# PY32F032xx register map
Vendor: Puya; Series: PY32F0; File version: 1.0.0
Arm 32-bit Cortex-M0+ Microcontroller based device, CPU clock up to 48 MHz.
CPU: CM0+ r0p1, little endian, no MPU, no FPU, 4 interrupt priority bits
Registers are 32-bit, read-write, reset 0x0 unless marked. A register's access mark holds for its fields unless they carry their own. Offsets are from the block's base; lines under a group give offsets from that group; [hi:lo] are bit positions; {n}, {i} and the like mark numbered series; 'fields as' and 'values as' point back to an identical list; <NAME> marks a mode.

## Memory map
0x40000400 TIM3 size 0x3F0
0x40002000 TIM14 size 0x400 — General purpose timer
0x40002800 RTC size 0x400 — Real time clock
0x40002C00 WWDG size 0x400 — Window watchdog
0x40003000 IWDG size 0x400 — Independent watchdog
0x40003800 SPI2 size 0x400
0x40004400 USART2 size 0x400
0x40004800 UART1 size 0x30
0x40004C00 UART2 size 0x30
0x40005400 I2C1 size 0x400 — Inter integrated circuit
0x40007000 PWR size 0x400 — Power control
0x40007C00 LPTIM size 0x400 — Low power timer
0x40008000 LPUART size 0x40
0x40010000 SYSCFG size 0x190 — System configuration controller
0x40010200 COMP size 0x20
0x40010300 OPA size 0x400 — Operational amplifier
0x40012400 ADC size 0x400 — Analog to Digital Converter
0x40012C00 TIM1 size 0x400 — Advanced timer
0x40013000 SPI1 size 0x400 — Serial peripheral interface
0x40013800 USART1 size 0x400 — Universal synchronous asynchronous receivertransmitter
0x40014400 TIM16 size 0x400 — General purpose timer
0x40014800 TIM17 size 0x400
0x40015800 DBGMCU size 0x400 — Debug support
0x40020000 DMA size 0x400 — Direct memory access
0x40021000 RCC size 0x400 — Reset and clock control
0x40021800 EXTI size 0x400 — External interrupt/eventcontroller
0x40022000 FLASH size 0x400
0x40023000 CRC size 0x400 — CRC calculation unit
0x50000000 GPIOA size 0x400 — General-purpose I/Os
0x50000400 GPIOB size 0x400
0x50001400 GPIOF size 0x400

## Interrupts
0 WWDG — Window WatchDog Interrupt
1 PVD (EXTI) — PVD Interrupt through EXTI Lines 16
2 RTC — RTC Interrupt through EXTI Lines 19
3 FLASH — FLASH global Interrupt
4 RCC — RCC global Interrupt
5 EXTI0_1 (EXTI) — EXTI Line 0 and 1 Interrupt
6 EXTI2_3 (EXTI) — EXTI Line 2 and 3 Interrupt
7 EXTI4_15 (EXTI) — EXTI Line 4 to 15 Interrupt
9 DMA_Channel1 (DMA) — DMA Channel 1 Interrupt
10 DMA_Channel2_3 (DMA) — DMA Channel 2 and Channel 3 Interrupt
12 ADC_COMP (ADC) — ADC and COMP Interrupt through EXTI Lines 17 and 18
13 TIM1_BRK_UP_TRG_COM (TIM1) — TIM1 Break, Update, Trigger and Commutation Interrupt
14 TIM1_CC (TIM1) — TIM1 Capture Compare Interrupt
17 LPTIM — LPTIM global Interrupt
19 TIM14 — TIM14 global Interrupt
21 TIM16 — TIM16 global Interrupt
22 TIM17 — TIM17 global Interrupt
23 I2C1 — I2C1 global Interrupt
25 SPI1 — SPI1 global Interrupt
26 SPI2 — SPI2 global Interrupt
27 USART1 — USART1 global Interrupt
28 USART2 — USART2 global Interrupt

## ADC — Analog to Digital Converter
Base 0x40012400
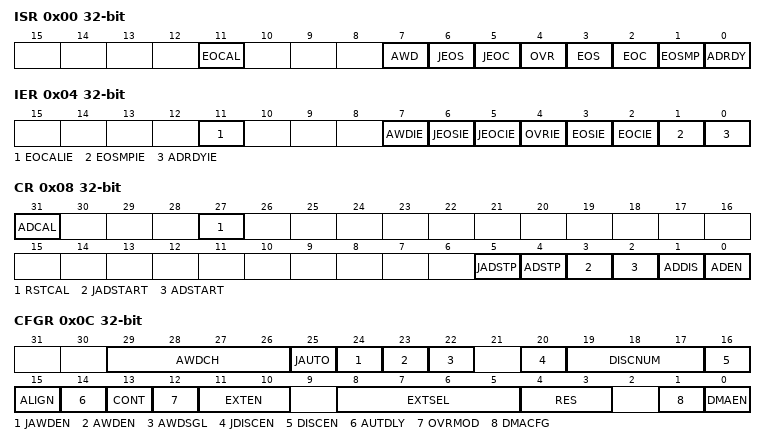
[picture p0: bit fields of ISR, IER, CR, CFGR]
0x00 ISR — ADC interrupt and status register
  [11] EOCAL, [7] AWD, [6] JEOS, [5] JEOC, [4] OVR, [3] EOS, [2] EOC, [1] EOSMP, [0] ADRDY
0x04 IER — ADC interrupt enable register
  [11] EOCALIE, [7] AWDIE, [6] JEOSIE, [5] JEOCIE, [4] OVRIE, [3] EOSIE, [2] EOCIE, [1] EOSMPIE, [0] ADRDYIE
0x08 CR — ADC control register
  [31] ADCAL, [27] RSTCAL, [5] JADSTP, [4] ADSTP, [3] JADSTART, [2] ADSTART, [1] ADDIS, [0] ADEN
0x0C CFGR
  [29:26] AWDCH
  [25] JAUTO
  [24] JAWDEN
  [23] AWDEN
  [22] AWDSGL
  [20] JDISCEN
  [19:17] DISCNUM
    1=0; 2=1; 4=2
  [16] DISCEN
  [15] ALIGN
  [14] AUTDLY
  [13] CONT
  [12] OVRMOD
  [11:10] EXTEN
    1=0; 2=1
  [8:5] EXTSEL
    1=0; 2=1; 4=2; 8=3
  [4:3] RES
    1=0; 2=1
  [1] DMACFG
  [0] DMAEN
0x10 CFGR2 — ADC configuration register 2
  [30:28] CALNUM
    1=0; 2=1; 4=2
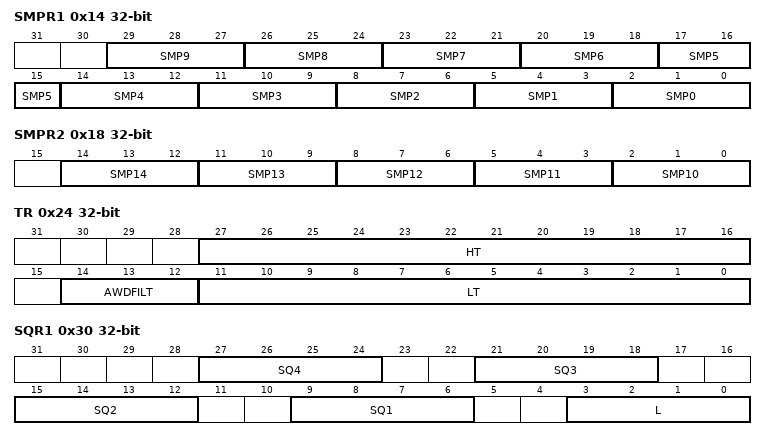
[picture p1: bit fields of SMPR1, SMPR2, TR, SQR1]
0x14 SMPR1 — ADC sampling time register 1
  [all] fields
    1=0; 2=1; 4=2
  [3n+2:3n] SMP{n} (n=0..9)
0x18 SMPR2
  [all] fields
    1=0; 2=1; 4=2
  [3n-28:3n-30] SMP{n} (n=10..14)
0x24 TR
  [27:16] HT
  [14:12] AWDFILT
    1=0; 2=1; 4=2
  [11:0] LT
0x30 SQR1
  [27:24] SQ4
  [21:18] SQ3
  [15:12] SQ2
  [9:6] SQ1
    1=0; 2=1; 4=2; 8=3
  [3:0] L
    1=0; 2=1; 4=2; 8=3
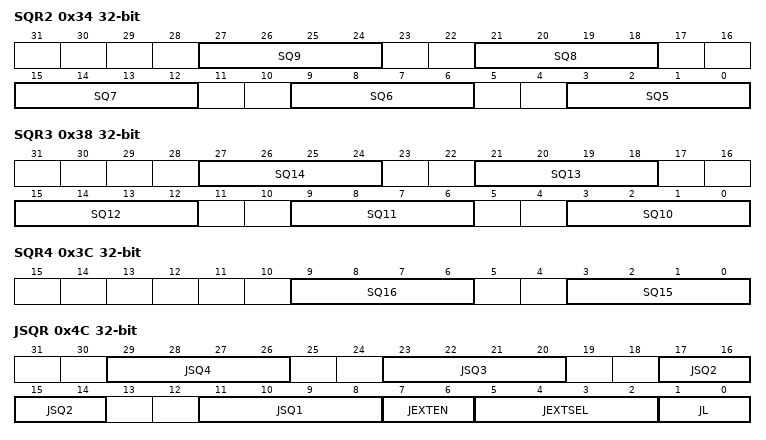
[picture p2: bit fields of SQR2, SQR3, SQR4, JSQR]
0x34 SQR2
  [all] fields
    1=0; 2=1; 4=2; 8=3
  [6n-27:6n-30] SQ{n} (n=5..9)
0x38 SQR3
  [all] fields
    1=0; 2=1; 4=2; 8=3
  [6n-57:6n-60] SQ{n} (n=10..14)
0x3C SQR4
  [9:6] SQ16
    1=0; 2=1; 4=2; 8=3
  [3:0] SQ15
    1=0; 2=1; 4=2; 8=3
0x40 DR — ADC group regular data register
  [15:0] RDATA ro
0x4C JSQR
  [6n+5:6n+2] JSQ{n} (n=1..4)
  [7:6] JEXTEN
    1=0; 2=1
  [5:2] JEXTSEL
    1=0; 2=1; 4=2; 8=3
  [1:0] JL
    1=0; 2=1
{0x7C+4i} JDR{i} (i=1..4)
  [15:0] JDATA ro
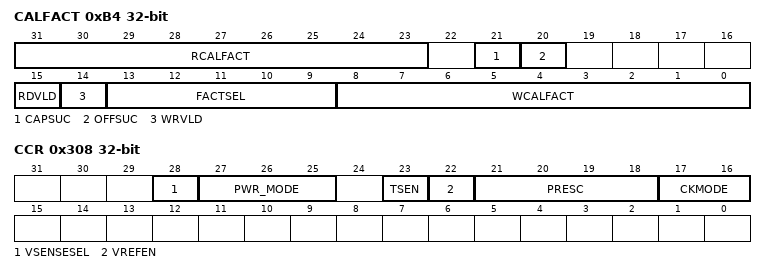
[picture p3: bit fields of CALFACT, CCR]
0xB4 CALFACT
  [31:23] RCALFACT ro
  [21] CAPSUC
  [20] OFFSUC
  [15] RDVLD
  [14] WRVLD
  [13:9] FACTSEL
    1=0; 2=1; 4=2; 8=3; 16=4
  [8:0] WCALFACT
0x308 CCR — ADC common configuration register
  [28] VSENSESEL
  [27:25] PWR_MODE
  [23] TSEN
  [22] VREFEN
  [21:18] PRESC
    1=0; 2=1; 4=2; 8=3
  [17:16] CKMODE
    1=0; 2=1
